# HDSC_HC32M424 register map
Vendor: HDSC; Series: ARMCM4; File version: 1.0
CPU: CM4 r0p1, little endian, MPU, FPU, 4 interrupt priority bits
Registers are 32-bit, read-write, reset 0x0 unless marked. A register's access mark holds for its fields unless they carry their own. Offsets are from the block's base; [hi:lo] are bit positions; {n}, {i} and the like mark numbered series.

## INTC
Base 0x40051000
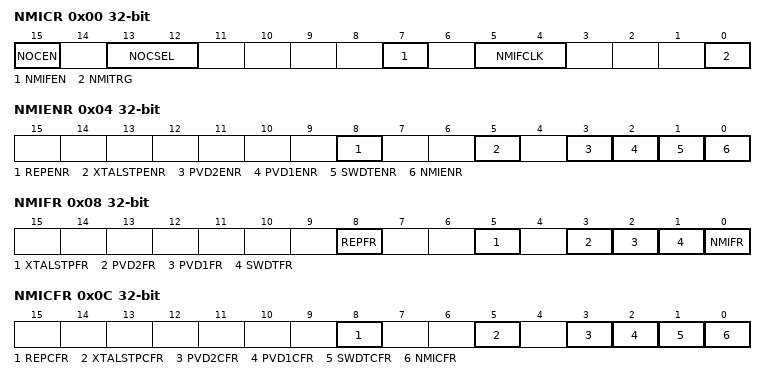
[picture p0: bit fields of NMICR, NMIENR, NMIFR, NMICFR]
0x00 NMICR
  [15] NOCEN, [13:12] NOCSEL, [7] NMIFEN, [5:4] NMIFCLK, [0] NMITRG
0x04 NMIENR
  [8] REPENR, [5] XTALSTPENR, [3] PVD2ENR, [2] PVD1ENR, [1] SWDTENR, [0] NMIENR
0x08 NMIFR ro
  [8] REPFR, [5] XTALSTPFR, [3] PVD2FR, [2] PVD1FR, [1] SWDTFR, [0] NMIFR
0x0C NMICFR
  [8] REPCFR, [5] XTALSTPCFR, [3] PVD2CFR, [2] PVD1CFR, [1] SWDTCFR, [0] NMICFR
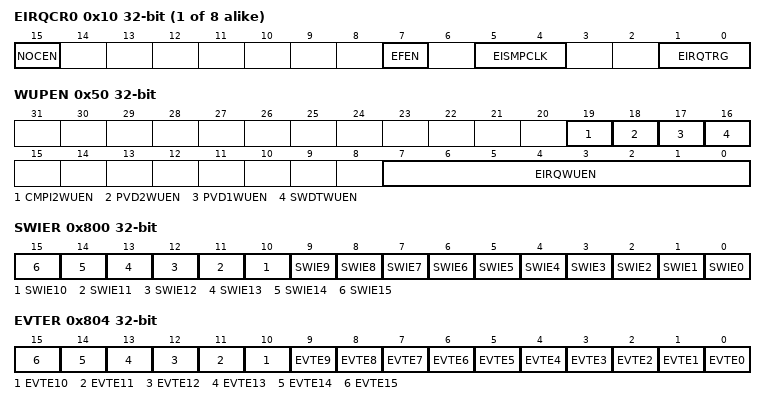
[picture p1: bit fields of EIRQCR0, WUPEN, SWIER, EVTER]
{0x10+4i} EIRQCR{i} (i=0..7)
  [15] NOCEN, [7] EFEN, [5:4] EISMPCLK, [1:0] EIRQTRG
0x50 WUPEN
  [19] CMPI2WUEN, [18] PVD2WUEN, [17] PVD1WUEN, [16] SWDTWUEN, [7:0] EIRQWUEN
0x54 EIRQFR ro
  [7:0] EIRQFR
0x58 EIRQCFR
  [7:0] EIRQCFR
{0x5C+4i} SEL{i} reset 0x1FF (i=0..7)
  [8:0] ISEL
0x7C SEL8
  [8:0] ISEL
0x80 SEL9 reset 0x1
  [8:0] ISEL
0x84 SEL10 reset 0x2
  [8:0] ISEL
0x88 SEL11 reset 0x3
  [8:0] ISEL
0x8C SEL12 reset 0x4
  [8:0] ISEL
0x90 SEL13 reset 0x5
  [8:0] ISEL
0x94 SEL14 reset 0x6
  [8:0] ISEL
0x98 SEL15 reset 0x7
  [8:0] ISEL
0x9C SEL16 reset 0x20
  [8:0] ISEL
0xA0 SEL17 reset 0x21
  [8:0] ISEL
0xA4 SEL18 reset 0x22
  [8:0] ISEL
0xA8 SEL19 reset 0x23
  [8:0] ISEL
0xAC SEL20 reset 0x24
  [8:0] ISEL
0xB0 SEL21 reset 0x25
  [8:0] ISEL
0xB4 SEL22 reset 0x26
  [8:0] ISEL
0xB8 SEL23 reset 0x27
  [8:0] ISEL
0xBC SEL24 reset 0x28
  [8:0] ISEL
0xC0 SEL25 reset 0x29
  [8:0] ISEL
0xC4 SEL26 reset 0x2A
  [8:0] ISEL
0xC8 SEL27 reset 0x2B
  [8:0] ISEL
0xCC SEL28 reset 0x2C
  [8:0] ISEL
0xD0 SEL29 reset 0x2D
  [8:0] ISEL
0xD4 SEL30 reset 0x2E
  [8:0] ISEL
0xD8 SEL31 reset 0x2F
  [8:0] ISEL
0xDC SEL32 reset 0x30
  [8:0] ISEL
0xE0 SEL33 reset 0x32
  [8:0] ISEL
0xE4 SEL34 reset 0x33
  [8:0] ISEL
0xE8 SEL35 reset 0x34
  [8:0] ISEL
0xEC SEL36 reset 0x37
  [8:0] ISEL
0xF0 SEL37 reset 0x40
  [8:0] ISEL
0xF4 SEL38 reset 0x41
  [8:0] ISEL
0xF8 SEL39 reset 0x42
  [8:0] ISEL
0xFC SEL40 reset 0x43
  [8:0] ISEL
0x100 SEL41 reset 0x55
  [8:0] ISEL
0x104 SEL42 reset 0x57
  [8:0] ISEL
0x108 SEL43 reset 0x100
  [8:0] ISEL
0x10C SEL44 reset 0x101
  [8:0] ISEL
0x110 SEL45 reset 0x102
  [8:0] ISEL
0x114 SEL46 reset 0x103
  [8:0] ISEL
0x118 SEL47 reset 0x104
  [8:0] ISEL
0x11C SEL48 reset 0x105
  [8:0] ISEL
0x120 SEL49 reset 0x106
  [8:0] ISEL
0x124 SEL50 reset 0x107
  [8:0] ISEL
0x128 SEL51 reset 0x108
  [8:0] ISEL
0x12C SEL52 reset 0x109
  [8:0] ISEL
0x130 SEL53 reset 0x10A
  [8:0] ISEL
0x134 SEL54 reset 0x10B
  [8:0] ISEL
0x138 SEL55 reset 0x10C
  [8:0] ISEL
0x13C SEL56 reset 0x10D
  [8:0] ISEL
0x140 SEL57 reset 0x10E
  [8:0] ISEL
0x144 SEL58 reset 0x10F
  [8:0] ISEL
0x148 SEL59 reset 0x110
  [8:0] ISEL
0x14C SEL60 reset 0x111
  [8:0] ISEL
0x150 SEL61 reset 0x116
  [8:0] ISEL
0x154 SEL62 reset 0x117
  [8:0] ISEL
0x158 SEL63 reset 0x118
  [8:0] ISEL
0x15C SEL64 reset 0x119
  [8:0] ISEL
0x160 SEL65 reset 0x11B
  [8:0] ISEL
0x164 SEL66 reset 0x11C
  [8:0] ISEL
0x168 SEL67 reset 0x11D
  [8:0] ISEL
0x16C SEL68 reset 0x11E
  [8:0] ISEL
0x170 SEL69 reset 0x120
  [8:0] ISEL
0x174 SEL70 reset 0x121
  [8:0] ISEL
0x178 SEL71 reset 0x122
  [8:0] ISEL
0x17C SEL72 reset 0x123
  [8:0] ISEL
0x180 SEL73 reset 0x125
  [8:0] ISEL
0x184 SEL74 reset 0x126
  [8:0] ISEL
0x188 SEL75 reset 0x127
  [8:0] ISEL
0x18C SEL76 reset 0x128
  [8:0] ISEL
0x190 SEL77 reset 0x12B
  [8:0] ISEL
0x194 SEL78 reset 0x12C
  [8:0] ISEL
0x198 SEL79 reset 0x12D
  [8:0] ISEL
0x19C SEL80 reset 0x12E
  [8:0] ISEL
0x1A0 SEL81 reset 0x140
  [8:0] ISEL
0x1A4 SEL82 reset 0x141
  [8:0] ISEL
0x1A8 SEL83 reset 0x142
  [8:0] ISEL
0x1AC SEL84 reset 0x143
  [8:0] ISEL
0x1B0 SEL85 reset 0x144
  [8:0] ISEL
0x1B4 SEL86 reset 0x145
  [8:0] ISEL
0x1B8 SEL87 reset 0x146
  [8:0] ISEL
0x1BC SEL88 reset 0x147
  [8:0] ISEL
0x1C0 SEL89 reset 0x148
  [8:0] ISEL
0x1C4 SEL90 reset 0x149
  [8:0] ISEL
0x1C8 SEL91 reset 0x14A
  [8:0] ISEL
0x1CC SEL92 reset 0x150
  [8:0] ISEL
0x1D0 SEL93 reset 0x151
  [8:0] ISEL
0x1D4 SEL94 reset 0x152
  [8:0] ISEL
0x1D8 SEL95 reset 0x153
  [8:0] ISEL
0x1DC SEL96 reset 0x154
  [8:0] ISEL
0x1E0 SEL97 reset 0x155
  [8:0] ISEL
0x1E4 SEL98 reset 0x156
  [8:0] ISEL
0x1E8 SEL99 reset 0x157
  [8:0] ISEL
0x1EC SEL100 reset 0x158
  [8:0] ISEL
0x1F0 SEL101 reset 0x159
  [8:0] ISEL
0x1F4 SEL102 reset 0x15A
  [8:0] ISEL
0x1F8 SEL103 reset 0x186
  [8:0] ISEL
0x1FC SEL104 reset 0x187
  [8:0] ISEL
0x200 SEL105 reset 0x188
  [8:0] ISEL
0x204 SEL106 reset 0x189
  [8:0] ISEL
0x208 SEL107 reset 0x18A
  [8:0] ISEL
0x20C SEL108 reset 0x18B
  [8:0] ISEL
0x210 SEL109 reset 0x18C
  [8:0] ISEL
0x214 SEL110 reset 0x18D
  [8:0] ISEL
0x218 SEL111 reset 0x18E
  [8:0] ISEL
0x21C SEL112 reset 0x18F
  [8:0] ISEL
0x220 SEL113 reset 0x190
  [8:0] ISEL
0x224 SEL114 reset 0x191
  [8:0] ISEL
0x228 SEL115 reset 0x192
  [8:0] ISEL
0x22C SEL116 reset 0x193
  [8:0] ISEL
0x230 SEL117 reset 0x194
  [8:0] ISEL
0x234 SEL118 reset 0x195
  [8:0] ISEL
0x238 SEL119 reset 0x196
  [8:0] ISEL
0x23C SEL120 reset 0x197
  [8:0] ISEL
0x240 SEL121 reset 0x198
  [8:0] ISEL
0x244 SEL122 reset 0x199
  [8:0] ISEL
0x248 SEL123 reset 0x19A
  [8:0] ISEL
0x24C SEL124 reset 0x19B
  [8:0] ISEL
0x250 SEL125 reset 0x19C
  [8:0] ISEL
0x254 SEL126 reset 0x1A0
  [8:0] ISEL
0x258 SEL127 reset 0x1A1
  [8:0] ISEL
0x25C SEL128 reset 0x1A2
  [8:0] ISEL
0x260 SEL129 reset 0x1A3
  [8:0] ISEL
0x264 SEL130 reset 0x1A4
  [8:0] ISEL
0x268 SEL131 reset 0x1A5
  [8:0] ISEL
0x26C SEL132 reset 0x1A6
  [8:0] ISEL
0x270 SEL133 reset 0x1A7
  [8:0] ISEL
0x274 SEL134 reset 0x1B0
  [8:0] ISEL
0x278 SEL135 reset 0x1B1
  [8:0] ISEL
0x27C SEL136 reset 0x1B2
  [8:0] ISEL
0x280 SEL137 reset 0x1B4
  [8:0] ISEL
0x284 SEL138 reset 0x1B5
  [8:0] ISEL
0x288 SEL139 reset 0x1B6
  [8:0] ISEL
0x28C SEL140 reset 0x1B8
  [8:0] ISEL
0x290 SEL141 reset 0x1C0
  [8:0] ISEL
0x294 SEL142 reset 0x1C1
  [8:0] ISEL
0x298 SEL143 reset 0x1C2
  [8:0] ISEL
0x29C SEL144 reset 0x1C3
  [8:0] ISEL
0x2A0 SEL145 reset 0x1C4
  [8:0] ISEL
0x2A4 SEL146 reset 0x1C5
  [8:0] ISEL
0x2A8 SEL147 reset 0x1C6
  [8:0] ISEL
0x2AC SEL148 reset 0x1C7
  [8:0] ISEL
0x2B0 SEL149 reset 0x1C9
  [8:0] ISEL
0x2B4 SEL150 reset 0x1CA
  [8:0] ISEL
0x2B8 SEL151 reset 0x1CB
  [8:0] ISEL
0x2BC SEL152 reset 0x1CC
  [8:0] ISEL
0x800 SWIER
  [n] SWIE{n} (n=0..15)
0x804 EVTER
  [n] EVTE{n} (n=0..15)
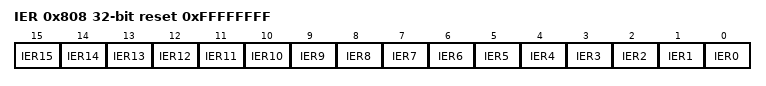
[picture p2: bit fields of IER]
0x808 IER reset 0xFFFFFFFF
  [n] IER{n} (n=0..15)
